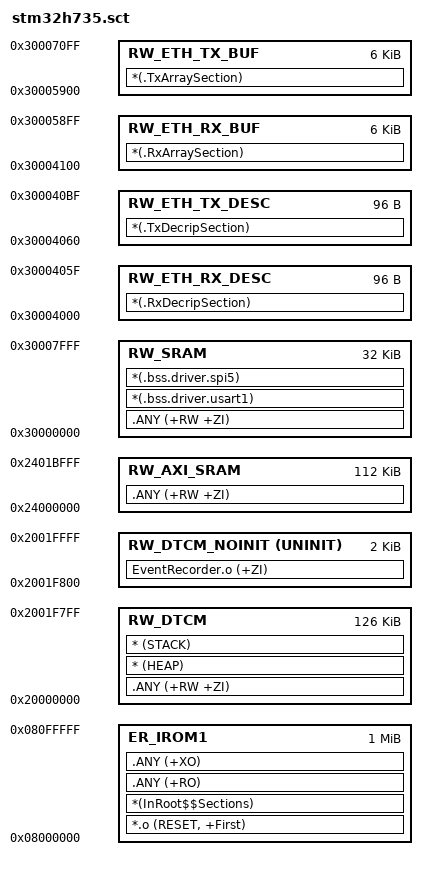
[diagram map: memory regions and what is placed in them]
; *************************************************************
; *** Scatter-Loading Description File generated by uVision ***
; *************************************************************

LR_IROM1 0x08000000 0x00100000  {      ; load region size_region
  ER_IROM1 0x08000000 0x00100000  {    ; load address = execution address
   *.o (RESET, +First)
   *(InRoot$$Sections)
   .ANY (+RO)
   .ANY (+XO)
  }
  RW_DTCM 0x20000000 0x0001F800  {
   .ANY (+RW +ZI)                      ; RW data
   * (HEAP)                            ; Heap
   * (STACK)                           ; Stack
  }
  RW_DTCM_NOINIT 0x2001F800 UNINIT 0x00000800  {
    EventRecorder.o (+ZI)
  }
  RW_AXI_SRAM 0x24000000 0x0001C000  { ; AXI RAM (16kB at the end (0x2401C000) is reserved for SDMMC1)
   .ANY (+RW +ZI)                      ; RW data
  }
  RW_SRAM 0x30000000 0x00008000  {     ; SRAM1 + SRAM2
   .ANY (+RW +ZI)                      ; RW data
   *(.bss.driver.usart1)
   *(.bss.driver.spi5)
  }
  RW_ETH_RX_DESC 0x30004000 0x00000060 {
    *(.RxDecripSection)
  }
  RW_ETH_TX_DESC 0x30004060 0x00000060 {
    *(.TxDecripSection)
  }
  RW_ETH_RX_BUF  0x30004100 0x00001800 {
    *(.RxArraySection)
  }
  RW_ETH_TX_BUF  0x30005900 0x00001800 {
    *(.TxArraySection)
  }
}
